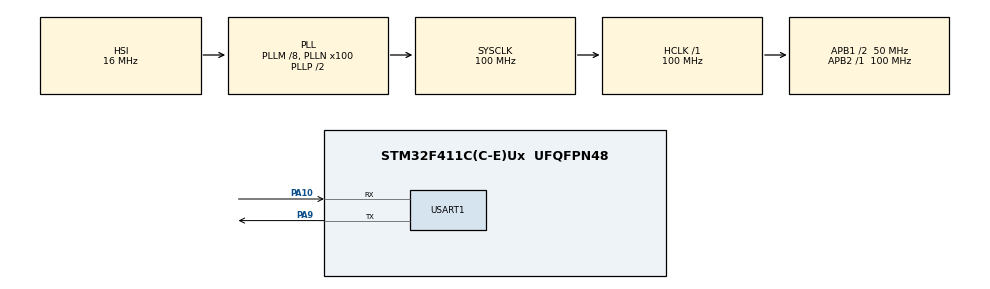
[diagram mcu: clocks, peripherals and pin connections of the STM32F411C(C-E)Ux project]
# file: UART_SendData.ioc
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Mcu.Family=STM32F4
Mcu.Name=STM32F411C(C-E)Ux
Mcu.Package=UFQFPN48
NVIC.PriorityGroup=NVIC_PRIORITYGROUP_4
PA10.Mode=Asynchronous
PA10.Signal=USART1_RX
PA13.Mode=Serial_Wire
PA13.Signal=SYS_JTMS-SWDIO
PA14.Mode=Serial_Wire
PA14.Signal=SYS_JTCK-SWCLK
PA9.Mode=Asynchronous
PA9.Signal=USART1_TX
PH0\ -\ OSC_IN.Mode=HSE-External-Oscillator
PH0\ -\ OSC_IN.Signal=RCC_OSC_IN
PH1\ -\ OSC_OUT.Mode=HSE-External-Oscillator
PH1\ -\ OSC_OUT.Signal=RCC_OSC_OUT
ProjectManager.HeapSize=0x200
ProjectManager.StackSize=0x400
ProjectManager.TargetToolchain=STM32CubeIDE
RCC.48MHZClocksFreq_Value=50000000
RCC.AHBFreq_Value=100000000
RCC.APB1CLKDivider=RCC_HCLK_DIV2
RCC.APB1Freq_Value=50000000
RCC.APB1TimFreq_Value=100000000
RCC.APB2Freq_Value=100000000
RCC.APB2TimFreq_Value=100000000
RCC.CortexFreq_Value=100000000
RCC.HCLKFreq_Value=100000000
RCC.HSE_VALUE=25000000
RCC.HSI_VALUE=16000000
RCC.LSE_VALUE=32768
RCC.PLLM=8
RCC.PLLN=100
RCC.SYSCLKFreq_VALUE=100000000
RCC.SYSCLKSource=RCC_SYSCLKSOURCE_PLLCLK
RCC.VCOOutputFreq_Value=200000000
USART1.VirtualMode=VM_ASYNC
board=custom

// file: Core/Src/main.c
/* USER CODE BEGIN Header */
/**
 ******************************************************************************
 * @file           : main.c
 * @brief          : Ejemplo integral de transmisión UART en STM32
 *                   Incluye:
 *                     - Transmisión básica de texto
 *                     - Transmisión de números
 *                     - Uso de colores ANSI en terminal
 *                     - Casteo de variables para transmisión
 ******************************************************************************
 * @attention
 * Requiere:
 *  - USART1 configurado en modo Asynchronous
 *  - Baudrate 115200, 8N1
 *  - Pines: PA9 (TX), PA10 (RX)
 ******************************************************************************
 */
/* USER CODE END Header */
#include "main.h"

/* USER CODE BEGIN Includes */
#include "string.h"
#include "stdio.h"
/* USER CODE END Includes */

/* USER CODE BEGIN PD */
#define ANSI_COLOR_RED     "\x1b[31m"
#define ANSI_COLOR_GREEN   "\x1b[32m"
#define ANSI_COLOR_YELLOW  "\x1b[33m"
#define ANSI_COLOR_BLUE    "\x1b[34m"
#define ANSI_COLOR_RESET   "\x1b[0m"
/* USER CODE END PD */

UART_HandleTypeDef huart1;

/* USER CODE BEGIN PV */
uint8_t msg_basic[] = "Hello World\r\n";
uint8_t number_u8 = 123;
int     number_int = 65535;
char    buffer[32];
/* USER CODE END PV */

void SystemClock_Config(void);
static void MX_GPIO_Init(void);
static void MX_USART1_UART_Init(void);
/* USER CODE BEGIN PFP */

/**
 * @brief Transmisión básica de texto fijo.
 */
void Example_BasicText(void);

/**
 * @brief Transmisión de un número entero de 0–255 (uint8_t).
 */
void Example_SendNumber_U8(uint8_t number);

/**
 * @brief Transmisión de un número entero grande (int) con casteo.
 */
void Example_SendNumber_Int(int number);

/**
 * @brief Ejemplo de colores en terminal mediante secuencias ANSI.
 */
void Example_Colors(int number);

/* USER CODE END PFP */

int main(void)
{

  /* MCU Configuration--------------------------------------------------------*/

  /* Reset of all peripherals, Initializes the Flash interface and the Systick. */
  HAL_Init();

  /* Configure the system clock */
  SystemClock_Config();

  /* Initialize all configured peripherals */
  MX_GPIO_Init();
  MX_USART1_UART_Init();
  /* USER CODE BEGIN 2 */

  /* Mensaje de inicio */
  uint8_t start_msg[] = "\r\n=== Ejemplo Integral UART STM32 ===\r\n";
  HAL_UART_Transmit(&huart1, start_msg, strlen((char*)start_msg), HAL_MAX_DELAY);

  /* USER CODE END 2 */

  /* Infinite loop */
  /* USER CODE BEGIN WHILE */
  while (1)
  {

      /* 1. Transmisión básica */
      Example_BasicText();
      HAL_Delay(1000);

      /* 2. Transmisión de número uint8_t */
      Example_SendNumber_U8(number_u8);
      HAL_Delay(1000);

      /* 3. Transmisión de número int con casteo */
      Example_SendNumber_Int(number_int);
      HAL_Delay(1000);

      /* 4. Transmisión con colores ANSI */
      Example_Colors(number_int);
      HAL_Delay(5000);

    /* USER CODE END WHILE */

  }
}

void SystemClock_Config(void)
{
  RCC_OscInitTypeDef RCC_OscInitStruct = {0};
  RCC_ClkInitTypeDef RCC_ClkInitStruct = {0};

  /** Configure the main internal regulator output voltage
  */
  __HAL_RCC_PWR_CLK_ENABLE();
  __HAL_PWR_VOLTAGESCALING_CONFIG(PWR_REGULATOR_VOLTAGE_SCALE1);

  /** Initializes the RCC Oscillators according to the specified parameters
  * in the RCC_OscInitTypeDef structure.
  */
  RCC_OscInitStruct.OscillatorType = RCC_OSCILLATORTYPE_HSI;
  RCC_OscInitStruct.HSIState = RCC_HSI_ON;
  RCC_OscInitStruct.HSICalibrationValue = RCC_HSICALIBRATION_DEFAULT;
  RCC_OscInitStruct.PLL.PLLState = RCC_PLL_ON;
  RCC_OscInitStruct.PLL.PLLSource = RCC_PLLSOURCE_HSI;
  RCC_OscInitStruct.PLL.PLLM = 8;
  RCC_OscInitStruct.PLL.PLLN = 100;
  RCC_OscInitStruct.PLL.PLLP = RCC_PLLP_DIV2;
  RCC_OscInitStruct.PLL.PLLQ = 4;
  if (HAL_RCC_OscConfig(&RCC_OscInitStruct) != HAL_OK)
  {
    Error_Handler();
  }

  /** Initializes the CPU, AHB and APB buses clocks
  */
  RCC_ClkInitStruct.ClockType = RCC_CLOCKTYPE_HCLK|RCC_CLOCKTYPE_SYSCLK
                              |RCC_CLOCKTYPE_PCLK1|RCC_CLOCKTYPE_PCLK2;
  RCC_ClkInitStruct.SYSCLKSource = RCC_SYSCLKSOURCE_PLLCLK;
  RCC_ClkInitStruct.AHBCLKDivider = RCC_SYSCLK_DIV1;
  RCC_ClkInitStruct.APB1CLKDivider = RCC_HCLK_DIV2;
  RCC_ClkInitStruct.APB2CLKDivider = RCC_HCLK_DIV1;

  if (HAL_RCC_ClockConfig(&RCC_ClkInitStruct, FLASH_LATENCY_3) != HAL_OK)
  {
    Error_Handler();
  }
}

static void MX_USART1_UART_Init(void)
{

  huart1.Instance = USART1;
  huart1.Init.BaudRate = 115200;
  huart1.Init.WordLength = UART_WORDLENGTH_8B;
  huart1.Init.StopBits = UART_STOPBITS_1;
  huart1.Init.Parity = UART_PARITY_NONE;
  huart1.Init.Mode = UART_MODE_TX_RX;
  huart1.Init.HwFlowCtl = UART_HWCONTROL_NONE;
  huart1.Init.OverSampling = UART_OVERSAMPLING_16;
  if (HAL_UART_Init(&huart1) != HAL_OK)
  {
    Error_Handler();
  }

}

static void MX_GPIO_Init(void)
{

  /* GPIO Ports Clock Enable */
  __HAL_RCC_GPIOH_CLK_ENABLE();
  __HAL_RCC_GPIOA_CLK_ENABLE();

}

/* USER CODE BEGIN 4 */

/**
 * @brief Transmisión básica de texto fijo.
 */
void Example_BasicText(void)
{
    HAL_UART_Transmit(&huart1, msg_basic, strlen((char*)msg_basic), HAL_MAX_DELAY);
}

/**
 * @brief Transmisión de un número entero de 0–255 (uint8_t).
 */
void Example_SendNumber_U8(uint8_t number)
{
    sprintf(buffer, "Numero uint8_t: %d\r\n", number);
    HAL_UART_Transmit(&huart1, (uint8_t*)buffer, strlen(buffer), HAL_MAX_DELAY);
}

/**
 * @brief Transmisión de un número entero grande (int) con casteo.
 */
void Example_SendNumber_Int(int number)
{
    sprintf(buffer, "Numero int: %d\r\n", number);
    HAL_UART_Transmit(&huart1, (uint8_t*)buffer, strlen(buffer), HAL_MAX_DELAY);
}

/**
 * @brief Ejemplo de colores en terminal mediante secuencias ANSI.
 */
void Example_Colors(int number)
{
    sprintf(buffer, ANSI_COLOR_RED   "Rojo:   %d\r\n" ANSI_COLOR_RESET, number);
    HAL_UART_Transmit(&huart1, (uint8_t*)buffer, strlen(buffer), HAL_MAX_DELAY);

    sprintf(buffer, ANSI_COLOR_GREEN "Verde:  %d\r\n" ANSI_COLOR_RESET, number);
    HAL_UART_Transmit(&huart1, (uint8_t*)buffer, strlen(buffer), HAL_MAX_DELAY);

    sprintf(buffer, ANSI_COLOR_YELLOW"Amarillo: %d\r\n" ANSI_COLOR_RESET, number);
    HAL_UART_Transmit(&huart1, (uint8_t*)buffer, strlen(buffer), HAL_MAX_DELAY);

    sprintf(buffer, ANSI_COLOR_BLUE  "Azul:   %d\r\n" ANSI_COLOR_RESET, number);
    HAL_UART_Transmit(&huart1, (uint8_t*)buffer, strlen(buffer), HAL_MAX_DELAY);
}
/* USER CODE END 4 */

void Error_Handler(void)
{
  __disable_irq();
  while (1)
  {
  }
}
